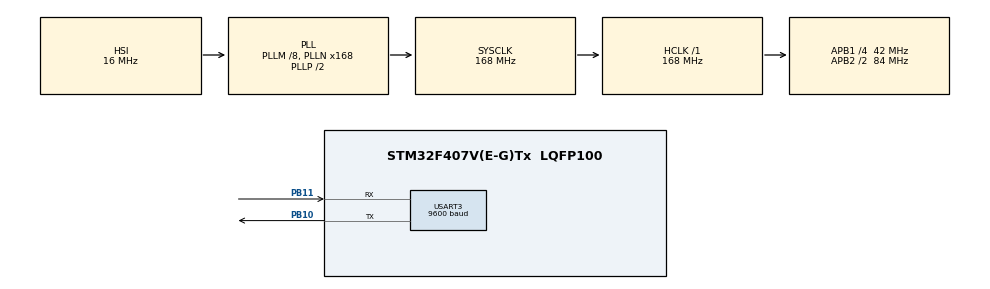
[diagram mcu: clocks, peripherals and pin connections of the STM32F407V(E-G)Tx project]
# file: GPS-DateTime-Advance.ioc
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Dma.Request0=USART3_RX
Dma.USART3_RX.0.Direction=DMA_PERIPH_TO_MEMORY
Dma.USART3_RX.0.FIFOMode=DMA_FIFOMODE_DISABLE
Dma.USART3_RX.0.Instance=DMA1_Stream1
Dma.USART3_RX.0.MemDataAlignment=DMA_MDATAALIGN_BYTE
Dma.USART3_RX.0.MemInc=DMA_MINC_ENABLE
Dma.USART3_RX.0.Mode=DMA_NORMAL
Dma.USART3_RX.0.PeriphDataAlignment=DMA_PDATAALIGN_BYTE
Dma.USART3_RX.0.PeriphInc=DMA_PINC_DISABLE
Dma.USART3_RX.0.Priority=DMA_PRIORITY_LOW
Mcu.Family=STM32F4
Mcu.Name=STM32F407V(E-G)Tx
Mcu.Package=LQFP100
NVIC.DMA1_Stream1_IRQn=true\:0\:0\:false\:false\:true\:false\:true
NVIC.PriorityGroup=NVIC_PRIORITYGROUP_4
NVIC.USART3_IRQn=true\:0\:0\:false\:false\:true\:true\:true
PB10.Mode=Asynchronous
PB10.Signal=USART3_TX
PB11.Mode=Asynchronous
PB11.Signal=USART3_RX
ProjectManager.HeapSize=0x200
ProjectManager.StackSize=0x400
ProjectManager.TargetToolchain=MDK-ARM V5.27
RCC.48MHZClocksFreq_Value=84000000
RCC.AHBFreq_Value=168000000
RCC.APB1CLKDivider=RCC_HCLK_DIV4
RCC.APB1Freq_Value=42000000
RCC.APB1TimFreq_Value=84000000
RCC.APB2CLKDivider=RCC_HCLK_DIV2
RCC.APB2Freq_Value=84000000
RCC.APB2TimFreq_Value=168000000
RCC.CortexFreq_Value=168000000
RCC.HCLKFreq_Value=168000000
RCC.HSE_VALUE=25000000
RCC.HSI_VALUE=16000000
RCC.LSE_VALUE=32768
RCC.PLLM=8
RCC.PLLN=168
RCC.SYSCLKFreq_VALUE=168000000
RCC.SYSCLKSource=RCC_SYSCLKSOURCE_PLLCLK
RCC.VCOOutputFreq_Value=336000000
USART3.BaudRate=9600
USART3.VirtualMode=VM_ASYNC
board=custom

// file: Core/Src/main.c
/* USER CODE BEGIN Header */
/**
  ******************************************************************************
  * @file           : main.c
  * @brief          : Main program body
  ******************************************************************************
  * @attention
  *
  * <h2><center>&copy; Copyright (c) 2024 STMicroelectronics.
  * All rights reserved.</center></h2>
  *
  * This software component is licensed by ST under BSD 3-Clause license,
  * the "License"; You may not use this file except in compliance with the
  * License. You may obtain a copy of the License at:
  *                        opensource.org/licenses/BSD-3-Clause
  *
  ******************************************************************************
  */
/* USER CODE END Header */
#include "main.h"
#include "dma.h"
#include "usart.h"
#include "gpio.h"

/* USER CODE BEGIN Includes */
#include "ALCD.h"
#include "CircularBuffer.h"
#include <string.h>
/* USER CODE END Includes */

/* USER CODE BEGIN PTD */
typedef struct {
  uint8_t     Hours;
  uint8_t     Minutes;
  uint8_t     Seconds;
  uint16_t    SubSeconds;
} GPS_UTC_Time;

typedef struct {
  uint8_t     Year;
  uint8_t     Month;
  uint8_t     Day;
} GPS_UTC_Date;

typedef void (*GPS_MessageHandleFn)(char* line);

typedef struct {
  const char*           MessageId;
  GPS_MessageHandleFn   process;
} GPS_MessageHandle;

/* USER CODE END PTD */

/* USER CODE BEGIN PD */
#define GPS_MSG_OFFSET         3
/* USER CODE END PD */

/* USER CODE BEGIN PV */
static uint8_t uart3RxBuf[1024];
static UART_CircularBuffer uart3Rx;

static GPS_UTC_Time gpsTime = {0};
static GPS_UTC_Date gpsDate = {0};
/* USER CODE END PV */

void SystemClock_Config(void);
/* USER CODE BEGIN PFP */
void GPS_process(char* line);
void GPS_RMC_process(char* line);
void GPS_GGA_process(char* line);
void GPS_GLL_process(char* line);
void GPS_GSV_process(char* line);

char* Str_indexOfAt(char* str, char c, int16_t num);
uint32_t Str_convertUNumFix(char* str, int16_t len);
/* USER CODE END PFP */

/* USER CODE BEGIN 0 */
#define GPS_HANDLE_INIT(T)        { #T, GPS_ ##T ##_process }
#define ARR_LEN(ARR)              sizeof(ARR) / sizeof(ARR[0])

static const GPS_MessageHandle GPS_MESSAGE_HANDLES[] = {
  GPS_HANDLE_INIT(RMC),
  GPS_HANDLE_INIT(GGA),
  GPS_HANDLE_INIT(GLL),
  GPS_HANDLE_INIT(GSV),
};
static const uint16_t GPS_MESSAGE_HANDLES_LEN = ARR_LEN(GPS_MESSAGE_HANDLES);
/* USER CODE END 0 */

int main(void)
{

  /* MCU Configuration--------------------------------------------------------*/

  /* Reset of all peripherals, Initializes the Flash interface and the Systick. */
  HAL_Init();

  /* Configure the system clock */
  SystemClock_Config();

  /* Initialize all configured peripherals */
  MX_GPIO_Init();
  MX_DMA_Init();
  MX_USART3_UART_Init();
  /* USER CODE BEGIN 2 */
  ALCD_init(16, 2);
  ALCD_clear();

  UART_CircularBuffer_init(&uart3Rx, &huart3, uart3RxBuf, sizeof(uart3RxBuf));
  UART_CircularBuffer_receive(&uart3Rx);
  /* USER CODE END 2 */

  /* Infinite loop */
  /* USER CODE BEGIN WHILE */
  while (1)
  {
    // Phase 1: Read Line
    if (UART_CircularBuffer_available(&uart3Rx) > 0) {
      int16_t idx = UART_CircularBuffer_findByte(&uart3Rx, '\n');
      if (idx >= 0) {
        char line[128];
        idx++;
        UART_CircularBuffer_readBytes(&uart3Rx, (uint8_t*) line, idx);
        line[idx] = '\0';
        // Process Line
        // Phase 2: Detect Message
        GPS_process(line);
      }
    }
    /* USER CODE END WHILE */

  }
}

void SystemClock_Config(void)
{
  RCC_OscInitTypeDef RCC_OscInitStruct = {0};
  RCC_ClkInitTypeDef RCC_ClkInitStruct = {0};

  /** Configure the main internal regulator output voltage
  */
  __HAL_RCC_PWR_CLK_ENABLE();
  __HAL_PWR_VOLTAGESCALING_CONFIG(PWR_REGULATOR_VOLTAGE_SCALE1);
  /** Initializes the RCC Oscillators according to the specified parameters
  * in the RCC_OscInitTypeDef structure.
  */
  RCC_OscInitStruct.OscillatorType = RCC_OSCILLATORTYPE_HSI;
  RCC_OscInitStruct.HSIState = RCC_HSI_ON;
  RCC_OscInitStruct.HSICalibrationValue = RCC_HSICALIBRATION_DEFAULT;
  RCC_OscInitStruct.PLL.PLLState = RCC_PLL_ON;
  RCC_OscInitStruct.PLL.PLLSource = RCC_PLLSOURCE_HSI;
  RCC_OscInitStruct.PLL.PLLM = 8;
  RCC_OscInitStruct.PLL.PLLN = 168;
  RCC_OscInitStruct.PLL.PLLP = RCC_PLLP_DIV2;
  RCC_OscInitStruct.PLL.PLLQ = 4;
  if (HAL_RCC_OscConfig(&RCC_OscInitStruct) != HAL_OK)
  {
    Error_Handler();
  }
  /** Initializes the CPU, AHB and APB buses clocks
  */
  RCC_ClkInitStruct.ClockType = RCC_CLOCKTYPE_HCLK|RCC_CLOCKTYPE_SYSCLK
                              |RCC_CLOCKTYPE_PCLK1|RCC_CLOCKTYPE_PCLK2;
  RCC_ClkInitStruct.SYSCLKSource = RCC_SYSCLKSOURCE_PLLCLK;
  RCC_ClkInitStruct.AHBCLKDivider = RCC_SYSCLK_DIV1;
  RCC_ClkInitStruct.APB1CLKDivider = RCC_HCLK_DIV4;
  RCC_ClkInitStruct.APB2CLKDivider = RCC_HCLK_DIV2;

  if (HAL_RCC_ClockConfig(&RCC_ClkInitStruct, FLASH_LATENCY_5) != HAL_OK)
  {
    Error_Handler();
  }
}

/* USER CODE BEGIN 4 */
void GPS_RMC_process(char* line) {
  char* start;
  char* end;
  // Get Time
  start = Str_indexOfAt(line, ',', 1);
  if (start) {
    start++;
    // hhmmss.sss
    gpsTime.Hours   = Str_convertUNumFix(&start[0], 2);
    gpsTime.Minutes = Str_convertUNumFix(&start[2], 2);
    gpsTime.Seconds = Str_convertUNumFix(&start[4], 2);
    gpsTime.SubSeconds = Str_convertUNumFix(&start[7], 3);
  }
  // Get Date
  start = Str_indexOfAt(line, ',', 9);
  if (start) {
    start++;
    // ddmmyy
    gpsDate.Day     = Str_convertUNumFix(&start[0], 2);
    gpsDate.Month   = Str_convertUNumFix(&start[2], 2);
    gpsDate.Year    = Str_convertUNumFix(&start[4], 2);
  }

  // Update time
  ALCD_printfXY(2, 0, "%02u:%02u:%02u.%03u", gpsTime.Hours, gpsTime.Minutes, gpsTime.Seconds, gpsTime.SubSeconds);
  ALCD_printfXY(4, 1, "%02u/%02u/%02u", gpsDate.Year, gpsDate.Month, gpsDate.Day);
}

void GPS_GGA_process(char* line) {
  //ALCD_clear();
  //ALCD_putsXY(0, 1, "GGA");
}
void GPS_GLL_process(char* line) {

}
void GPS_GSV_process(char* line) {

}
void GPS_process(char* line) {
  // Check '$'
  if (line[0] != '$') {
    return;
  }
  // Find Message
  // Simple Way
  /*for (uint8_t i = 0; i < GPS_MESSAGE_HANDLES_LEN; i++) {
    if (strncmp(&line[GPS_MSG_OFFSET], GPS_MESSAGE_HANDLES[i].MessageId, 3) == 0) {
      GPS_MESSAGE_HANDLES[i].process(line);
      break;
    }
  }*/
  // Faster Way, Linear Search
  const GPS_MessageHandle* pHandle = GPS_MESSAGE_HANDLES;
  uint16_t len = GPS_MESSAGE_HANDLES_LEN;
  while (len-- > 0) {
    if (strncmp(&line[GPS_MSG_OFFSET], pHandle->MessageId, 3) == 0) {
      pHandle->process(line);
      break;
    }
    pHandle++;
  }
}

char* Str_indexOfAt(char* str, char c, int16_t num) {
  if (*str == c) {
    num--;
  }

  while (num-- > 0) {
    str = strchr(str + 1, c);
  }

  return str;
}

uint32_t Str_convertUNumFix(char* str, int16_t len) {
  uint32_t z = 0;

  while (*str != NULL && len-- > 0) {
    if (*str < '0' || *str > '9') {
      break;
    }

    z = (z * 10) + (*str - 0x30);
    str++;
  }

  return z;
}

void HAL_UART_ErrorCallback(UART_HandleTypeDef* huart) {
  switch ((uint32_t) huart->Instance) {
    case USART3_BASE:
      UART_CircularBuffer_resetIO(&uart3Rx);
      UART_CircularBuffer_receive(&uart3Rx);
      break;
  }
}

void HAL_UART_RxCpltCallback(UART_HandleTypeDef* huart) {
  switch ((uint32_t) huart->Instance) {
    case USART3_BASE:
      UART_CircularBuffer_handleRx(&uart3Rx);
      break;
  }
}
/* USER CODE END 4 */

void Error_Handler(void)
{
  __disable_irq();
  while (1)
  {
  }
}

/************************ (C) COPYRIGHT STMicroelectronics *****END OF FILE****/
